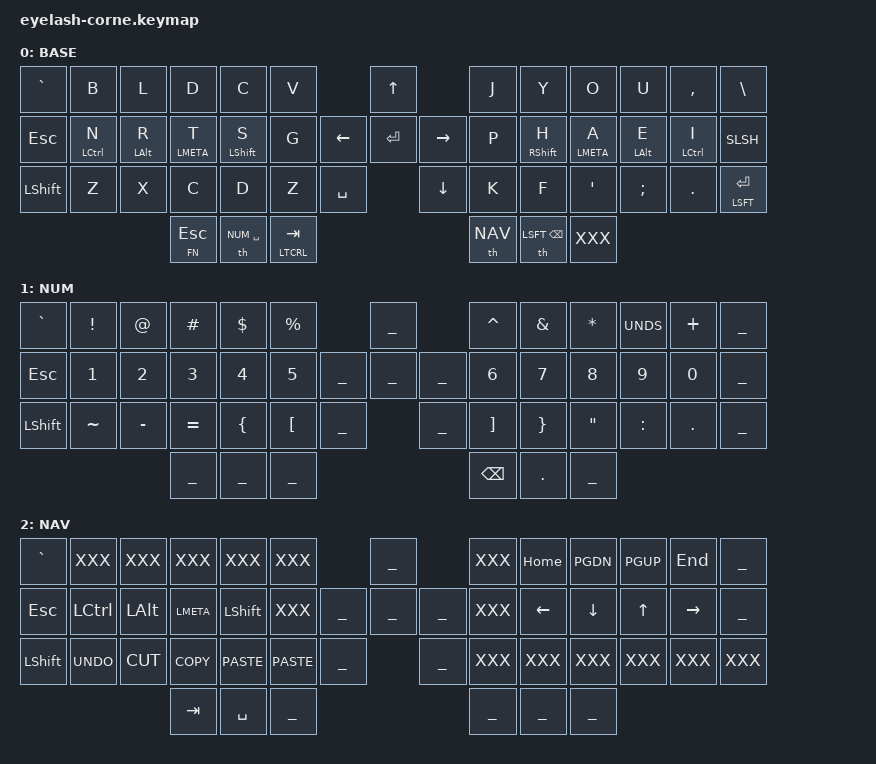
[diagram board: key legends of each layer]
/*                                      42 KEY MATRIX / LAYOUT MAPPING

  ╭────────────────────────┬────────────────────────╮ ╭─────────────────────────┬─────────────────────────╮
  │  0   1   2   3   4   5 │  6   7   8   9  10  11 │ │ LT5 LT4 LT3 LT2 LT1 LT0 │ RT0 RT1 RT2 RT3 RT4 RT5 │
  │ 12  13  14  15  16  17 │ 18  19  20  21  22  23 │ │ LM5 LM4 LM3 LM2 LM1 LM0 │ RM0 RM1 RM2 RM3 RM4 RM5 │
  │ 24  25  26  27  28  29 │ 30  31  32  33  34  35 │ │ LB5 LB4 LB3 LB2 LB1 LB0 │ RB0 RB1 RB2 RB3 RB4 RB5 │
  ╰───────────╮ 36  37  38 │ 39  40  41 ╭───────────╯ ╰───────────╮ LH2 LH1 LH0 │ RH0 RH1 RH2 ╭───────────╯
              ╰────────────┴────────────╯                         ╰─────────────┴─────────────╯             */

#include "zmk-helpers/key-labels/42.h"
#include "base.keymap"

#define CONFIG_WIRELESS

#include <behaviors.dtsi>
#include <dt-bindings/zmk/bt.h>
#include <dt-bindings/zmk/keys.h>
#include <dt-bindings/zmk/mouse.h>
#include <dt-bindings/zmk/outputs.h>
#include <dt-bindings/zmk/rgb.h>

// def num nav gam fn sys mouse

/ {
  // behaviors {
  //   td0: td0 {
  //     compatible = "zmk,behavior-tap-dance";
  //     #binding-cells = <0>;
  //     bindings = <&kp LEFT_SHIFT>, <&kp CAPS>;
  //   };
  // };

  rgb_encoder: rgb_encoder {
    compatible = "zmk,behavior-sensor-rotate";
    #sensor-binding-cells = <0>;
    bindings = <&rgb_ug RGB_BRI>, <&rgb_ug RGB_BRD>;
  };

  keymap {
    compatible = "zmk,keymap";

    default_layer {
      display-name = "BASE";

      bindings = <
&kp GRAVE  &kp B        &kp L       &kp D        &kp C         &kp V                               &kp UP                &kp J         &kp Y         &kp O         &kp U         &kp COMMA     &kp BSLH
&kp ESC    &hml LCTRL N &hml LALT R &hml LMETA T &hml LSHFT S  &kp G                     &kp LEFT  &kp ENTER  &kp RIGHT  &kp P         &hmr RSHFT H  &hmr LMETA A  &hmr LALT E   &hmr LCTRL I  &kp SLSH
&kp LSHFT  &kp Z        &kp X       &kp C        &kp D         &kp Z         &kp SPACE             &kp DOWN              &kp K         &kp F         &kp SQT       &kp SEMI      &kp DOT       &mt LSFT RET
                                    &mt FN ESC   &th NUM SPC   &mt LTCRL TAB                                             &th NAV       &th LSFT BSPC  XXX             
      >;

      sensor-bindings = <&inc_dec_kp C_VOLUME_UP C_VOLUME_DOWN>;
    };

    num_layer {
      display-name = "NUM";

      bindings = <
&kp GRAVE  &kp EXCL   &kp AT     &kp HASH   &kp DOLLAR &kp PERCENT          ___      &kp CARET     &kp AMPS      &kp STAR      &kp UNDS      &kp PLUS      ___
&kp ESC    &kp N1     &kp N2     &kp N3     &kp N4     &kp N5           ___ ___ ___  &kp N6        &kp N7        &kp N8        &kp N9        &kp N0        ___
&kp LSHFT  &kp TILDE  &kp MINUS  &kp EQUAL  &kp LBRC   &kp LBKT    ___      ___      &kp RBKT      &kp RBRC      &kp DQT       &kp COLON     &kp DOT       ___
                                  ___       ___        ___                                     &kp BSPC      &kp DOT       ___             
      >;

      sensor-bindings = <&inc_dec_kp PG_UP PG_DN>;
    };

    nav_layer {
      display-name = "NAV";

      bindings = <
&kp GRAVE  XXX        XXX        XXX         XXX          XXX                  ___      XXX  &kp HOME   &kp PGDN  &kp PGUP  &kp END    ___
&kp ESC    &kp LCTRL  &kp LALT   &kp LMETA   &kp LSHFT    XXX              ___ ___ ___  XXX  &kp LEFT   &kp DOWN  &kp UP    &kp RIGHT  ___
&kp LSHFT  &kp K_UNDO &kp K_CUT  &kp K_COPY  &kp K_PASTE  &kp K_PASTE ___      ___      XXX  XXX        XXX       XXX       XXX        XXX                      
                                 &kp TAB     &kp SPACE     ___                          ___   ___       ___         
      >;

      sensor-bindings = <&rgb_encoder>;
    };
  };
};

// ZMKMAP(Gaming,
// &kp T         &kp TAB       &kp Q         &kp W         &kp E         &kp R           &kp Y         &kp U         &kp I         &kp O         &kp P         &kp F5   
// &kp G         &kp ESC       &kp A         &kp S         &kp D         &kp F           &kp H         &kp J         &kp K         &kp L         &kp SEMI      &kp SQT
// &kp B         &kp LSHFT     &kp Z         &kp X         &kp C         &kp V           &kp N         &kp M         &kp COMMA     &kp DOT       &kp SLSH      &kp RET
//                                           &kp LALT      &kp SPC       &kp LCTRL       &kp LMETA     &kp BSPC      EXIT
// )

// ZMK_KEYMAP(Fn,
// &kp GRAVE     XXX           XXX           XXX           XXX           XXX             XXX           XXX           XXX           XXX           XXX           &kp DEL
// &kp ESC       XXX           XXX           XXX           XXX           XXX             XXX           XXX           XXX           XXX           XXX           &kp BSLH      
// &kp LSHFT     XXX           XXX           XXX           XXX           XXX             XXX           XXX           XXX           XXX           XXX           &kp ENTER     
//                                           XXX           XXX           XXX             XXX             XXX         XXX  
// )
// ZMK_KEYMAP(Sys,
// &kp GRAVE     XXX           XXX           XXX           XXX           XXX             XXX           XXX           XXX           XXX           XXX           &kp DEL
// &kp ESC       XXX           XXX           XXX           XXX           XXX             XXX           XXX           XXX           XXX           XXX           &kp BSLH      
// &kp LSHFT     XXX           XXX           XXX           XXX           XXX             XXX           XXX           XXX           XXX           XXX           &kp ENTER     
//                                           XXX           XXX           XXX             XXX             XXX         XXX             
// )
// ZMK_KEYMAP(Mouse,
// XXX           XXX           XXX           XXX           XXX           XXX             XXX           XXX           XXX           XXX           XXX           XXX          
// XXX           XXX           XXX           XXX           XXX           XXX             XXX           XXX           XXX           XXX           XXX           XXX          
// XXX           XXX           XXX           XXX           XXX           XXX             XXX           XXX           XXX           XXX           XXX           XXX          
//                                           XXX           XXX           XXX             XXX             XXX         XXX             

// )

// ZMK_KEYMAP(Blank,
// //╭─────────────┬─────────────┬─────────────┬─────────────┬─────────────┬─────────────╮ ╭─────────────┬─────────────┬─────────────┬─────────────┬─────────────┬─────────────╮
//     XXX           XXX           XXX           XXX           XXX           XXX             XXX           XXX           XXX           XXX           XXX           XXX          
//     XXX           XXX           XXX           XXX           XXX           XXX             XXX           XXX           XXX           XXX           XXX           XXX          
//     XXX           XXX           XXX           XXX           XXX           XXX             XXX           XXX           XXX           XXX           XXX           XXX          
// //╰─────────────┼─────────────┼─────────────┴─────────────┼─────────────┼─────────────┤ ├─────────────┼─────────────┼─────────────┴─────────────┴─────────────┴─────────────╯
//                                               XXX           XXX           XXX             XXX             XXX         XXX             
// //                                          ╰─────────────┴─────────────┴─────────────╯ ╰─────────────┴─────────────┴─────────────╯
// )
